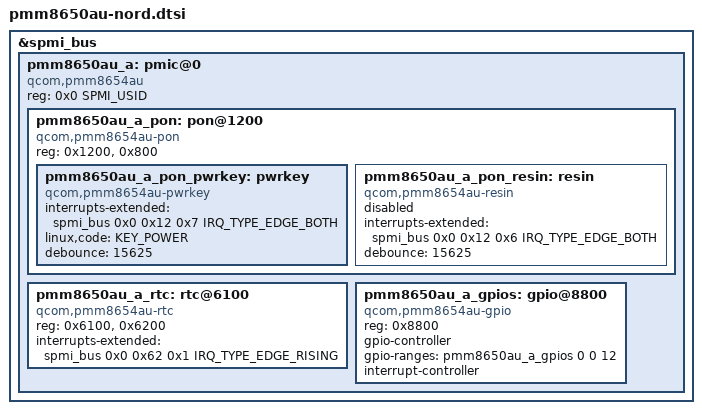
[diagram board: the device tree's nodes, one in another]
// SPDX-License-Identifier: BSD-3-Clause
/*
 * Copyright (c) Qualcomm Technologies, Inc. and/or its subsidiaries.
 */

#include <dt-bindings/input/linux-event-codes.h>
#include <dt-bindings/interrupt-controller/irq.h>
#include <dt-bindings/spmi/spmi.h>

&spmi_bus {
	pmm8650au_a: pmic@0 {
		compatible = "qcom,pmm8654au", "qcom,spmi-pmic";
		reg = <0x0 SPMI_USID>;
		#address-cells = <1>;
		#size-cells = <0>;

		pmm8650au_a_pon: pon@1200 {
			compatible = "qcom,pmm8654au-pon", "qcom,pmk8350-pon";
			reg = <0x1200>, <0x800>;
			reg-names = "hlos", "pbs";

			pmm8650au_a_pon_pwrkey: pwrkey {
				compatible = "qcom,pmm8654au-pwrkey", "qcom,pmk8350-pwrkey";
				interrupts-extended = <&spmi_bus 0x0 0x12 0x7 IRQ_TYPE_EDGE_BOTH>;
				linux,code = <KEY_POWER>;
				debounce = <15625>;
			};

			pmm8650au_a_pon_resin: resin {
				compatible = "qcom,pmm8654au-resin", "qcom,pmk8350-resin";
				interrupts-extended = <&spmi_bus 0x0 0x12 0x6 IRQ_TYPE_EDGE_BOTH>;
				debounce = <15625>;
				status = "disabled";
			};
		};

		pmm8650au_a_rtc: rtc@6100 {
			compatible = "qcom,pmm8654au-rtc", "qcom,pmk8350-rtc";
			reg = <0x6100>, <0x6200>;
			reg-names = "rtc", "alarm";
			interrupts-extended = <&spmi_bus 0x0 0x62 0x1 IRQ_TYPE_EDGE_RISING>;
		};

		pmm8650au_a_gpios: gpio@8800 {
			compatible = "qcom,pmm8654au-gpio", "qcom,spmi-gpio";
			reg = <0x8800>;
			gpio-controller;
			gpio-ranges = <&pmm8650au_a_gpios 0 0 12>;
			#gpio-cells = <2>;
			interrupt-controller;
			#interrupt-cells = <2>;
		};
	};
};
